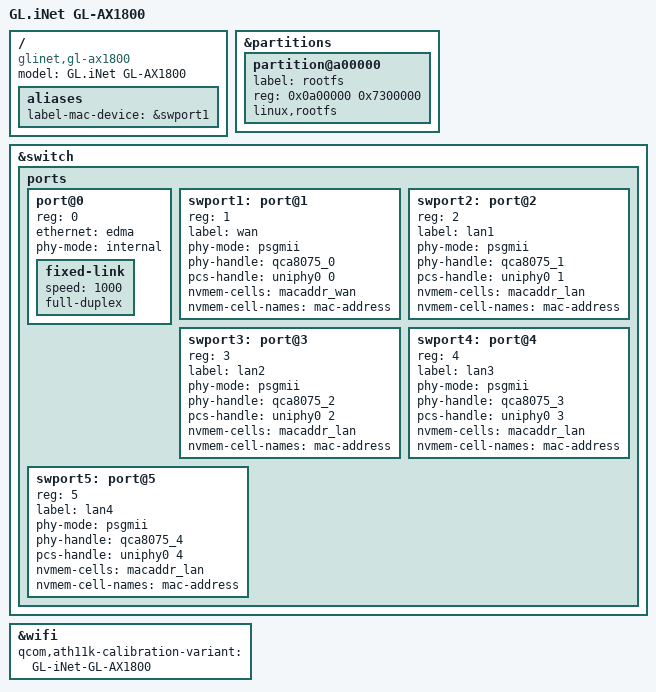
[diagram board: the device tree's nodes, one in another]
// SPDX-License-Identifier: GPL-2.0-or-later OR MIT

/dts-v1/;

#include "ipq6000-glinet.dtsi"

/ {
	model = "GL.iNet GL-AX1800";
	compatible = "glinet,gl-ax1800", "qcom,ipq6018";

	aliases {
		label-mac-device = &swport1;
	};
};

&partitions {
	partition@a00000 {
		label = "rootfs";
		reg = <0x0a00000 0x7300000>;
		linux,rootfs;
	};
};

&switch {
	status = "okay";

	ports {
		#address-cells = <1>;
		#size-cells = <0>;

		port@0 {
			reg = <0>;
			ethernet = <&edma>;
			phy-mode = "internal";

			fixed-link {
				speed = <1000>;
				full-duplex;
			};
		};

		swport1: port@1 {
			reg = <1>;
			label = "wan";
			phy-mode = "psgmii";
			phy-handle = <&qca8075_0>;
			pcs-handle = <&uniphy0 0>;
			nvmem-cells = <&macaddr_wan>;
			nvmem-cell-names = "mac-address";
		};

		swport2: port@2 {
			reg = <2>;
			label = "lan1";
			phy-mode = "psgmii";
			phy-handle = <&qca8075_1>;
			pcs-handle = <&uniphy0 1>;
			nvmem-cells = <&macaddr_lan>;
			nvmem-cell-names = "mac-address";
		};

		swport3: port@3 {
			reg = <3>;
			label = "lan2";
			phy-mode = "psgmii";
			phy-handle = <&qca8075_2>;
			pcs-handle = <&uniphy0 2>;
			nvmem-cells = <&macaddr_lan>;
			nvmem-cell-names = "mac-address";
		};

		swport4: port@4 {
			reg = <4>;
			label = "lan3";
			phy-mode = "psgmii";
			phy-handle = <&qca8075_3>;
			pcs-handle = <&uniphy0 3>;
			nvmem-cells = <&macaddr_lan>;
			nvmem-cell-names = "mac-address";
		};

		swport5: port@5 {
			reg = <5>;
			label = "lan4";
			phy-mode = "psgmii";
			phy-handle = <&qca8075_4>;
			pcs-handle = <&uniphy0 4>;
			nvmem-cells = <&macaddr_lan>;
			nvmem-cell-names = "mac-address";
		};
	};
};

&wifi {
	qcom,ath11k-calibration-variant = "GL-iNet-GL-AX1800";
};
